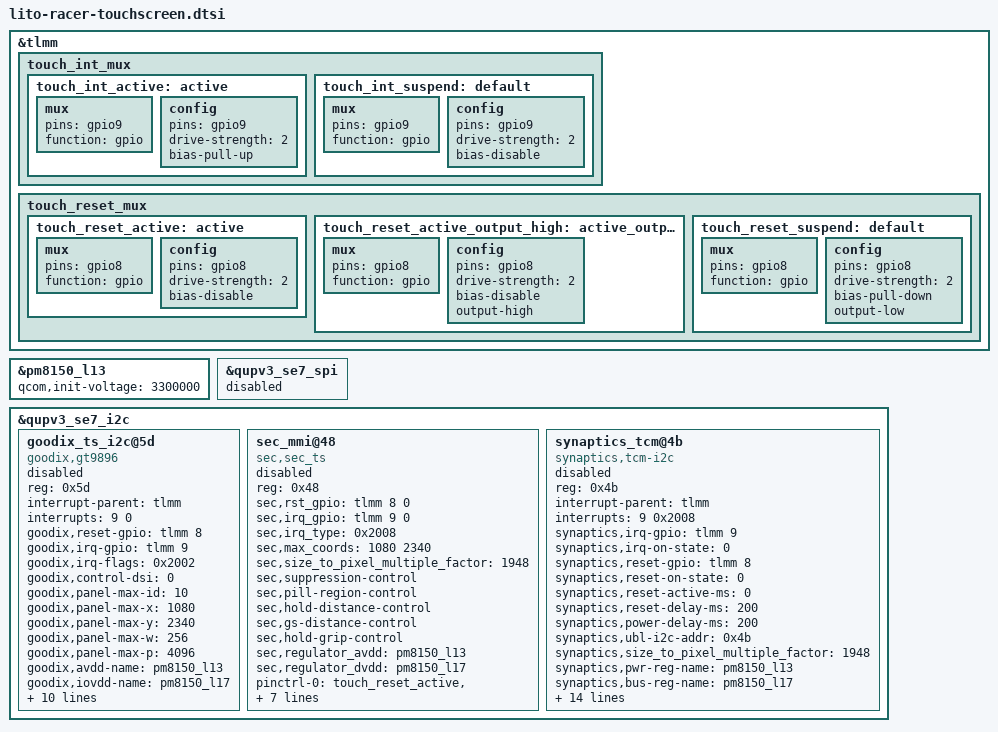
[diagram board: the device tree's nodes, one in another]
&tlmm {
	touch_int_mux {
		touch_int_active: active {
			mux {
				pins = "gpio9";
				function = "gpio";
			};
			config {
				pins = "gpio9";
				drive-strength = <2>;
				bias-pull-up;
			};
		};

		touch_int_suspend: default {
			mux {
				pins = "gpio9";
				function = "gpio";
			};
			config {
				pins = "gpio9";
				drive-strength = <2>;
				bias-disable;
			};
		};
	};

	touch_reset_mux {
		touch_reset_active: active {
			mux {
				pins = "gpio8";
				function = "gpio";
			};
			config {
				pins = "gpio8";
				drive-strength = <2>;
				bias-disable;
			};
		};

		touch_reset_active_output_high: active_output_high {
			mux {
				pins = "gpio8";
				function = "gpio";
			};
			config {
				pins = "gpio8";
				drive-strength = <2>;
				bias-disable;
				output-high;
			};
		};

		touch_reset_suspend: default {
			mux {
				pins = "gpio8";
				function = "gpio";
			};
			config {
				pins = "gpio8";
				drive-strength = <2>;
				bias-pull-down;
				output-low;
			};
		};
	};
};

&pm8150_l13 {
	qcom,init-voltage = <3300000>;
};

&qupv3_se7_spi {
	status = "disabled";
};

&qupv3_se7_i2c {
	status = "ok";
	goodix_ts_i2c@5d {
		compatible = "goodix,gt9896";
		reg = <0x5d>;
		status = "/chosen","mmi,panel_name","contains","boe_gdx","csot_gdx";
		interrupt-parent = <&tlmm>;
		interrupts = <9 0>;
		goodix,reset-gpio = <&tlmm 8 0x0>;
		goodix,irq-gpio = <&tlmm 9 0x2002>;
		goodix,irq-flags = <0x2002>; /* 1:trigger rising, 2:trigger falling;*/
		goodix,control-dsi = <0>;
		goodix,panel-max-id = <10>;
		goodix,panel-max-x = <1080>;
		goodix,panel-max-y = <2340>;
		goodix,panel-max-w = <256>;
		goodix,panel-max-p = <4096>;
		goodix,avdd-name = "pm8150_l13";
		goodix,iovdd-name = "pm8150_l17";
		goodix,power-on-delay-us = <300000>; /*300ms*/
		goodix,power-off-delay-us = <5000>;
		/*goodix,swap-axis;*/
		goodix,usb_charger;
		goodix,cfg_bin_name = "goodix_cfg_group_boe_racerl.bin";
		pinctrl-names = "pmx_ts_active", "pmx_ts_suspend";
		pinctrl-0 = <&touch_reset_active &touch_int_active>;
		pinctrl-1 = <&touch_reset_suspend &touch_int_suspend>;
		/* touchscreen_mmi class entries */
		mmi,class-entry-name = "GTx8";
	};

	sec_mmi@48 {
		status = "/chosen", "mmi,panel_name","contains","csot_lsi","boe_lsi";
		compatible = "sec,sec_ts";
		reg = <0x48>;
		sec,rst_gpio = <&tlmm 8 0>;
		sec,irq_gpio = <&tlmm 9 0>;
		sec,irq_type = <0x2008>; /*IRQF_TRIGGER_LOW | IRQF_ONESHOT*/
		sec,max_coords = <1080 2340>;
		sec,size_to_pixel_multiple_factor = <1948>;
		sec,suppression-control;
		sec,pill-region-control;
		sec,hold-distance-control;
		sec,gs-distance-control;
		sec,hold-grip-control;
		sec,regulator_avdd = "pm8150_l13";
		sec,regulator_dvdd = "pm8150_l17";
		pinctrl-names = "on_state", "off_state";
		pinctrl-0 = <&touch_reset_active &touch_int_active>;
		pinctrl-1 = <&touch_reset_suspend &touch_int_suspend>;
		/* touchscreen_mmi class entries */
		mmi,refresh-rate-update;
		mmi,enable-gestures;
		mmi,usb-charger-detection;
		mmi,power-off-suspend;
	};

	synaptics_tcm@4b {
		status = "/chosen","mmi,panel_name","contains","tianma_syna";
		compatible = "synaptics,tcm-i2c";
		reg = <0x4b>;
		interrupt-parent = <&tlmm>;
		interrupts = <9 0x2008>;
		synaptics,irq-gpio = <&tlmm 9 0x2008>; /*IRQF_TRIGGER_LOW | IRQF_ONESHOT*/
		synaptics,irq-on-state = <0>;
		synaptics,reset-gpio = <&tlmm 8 0x0000>;
		synaptics,reset-on-state = <0>;
		synaptics,reset-active-ms = <0>;
		synaptics,reset-delay-ms = <200>;
		synaptics,power-delay-ms = <200>;
		synaptics,ubl-i2c-addr = <0x4b>;
		synaptics,size_to_pixel_multiple_factor = <1948>;
		synaptics,pwr-reg-name = "pm8150_l13";
		synaptics,bus-reg-name = "pm8150_l17";
		pinctrl-names = "ts_mmi_on_state", "ts_mmi_off_state";
		pinctrl-0 = <&touch_reset_active_output_high &touch_int_active>;
		pinctrl-1 = <&touch_reset_suspend &touch_int_suspend>;
		/* touchscreen_mmi class entries */
		mmi,max_coords = <1080 2340>;
		mmi,enable-gestures;
		mmi,usb-charger-detection;
		mmi,power-off-suspend;
		mmi,suppression-control;
		mmi,gs-distance-control;
		mmi,pill-region-control;
		mmi,hold-distance-control;
		mmi,poison-slot-control;
		mmi,fps_detection;
	};
};
